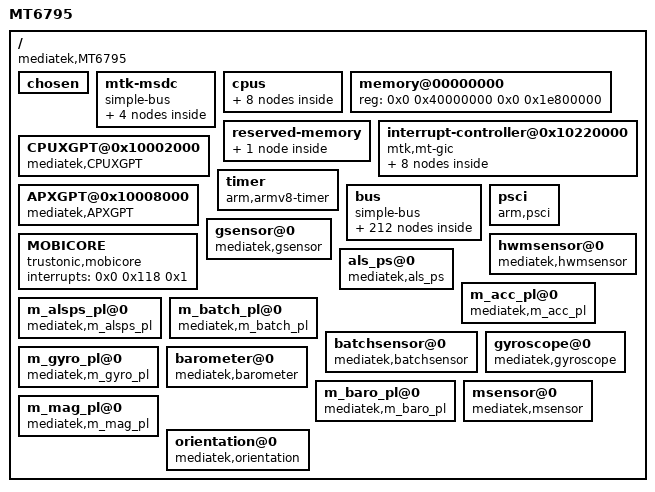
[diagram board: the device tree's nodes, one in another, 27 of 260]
/*
 * Mediatek's MT6795 SoC device tree source
 *
 * Copyright (c) 2013 MediaTek Co., Ltd.
 *              http://www.mediatek.com
 *
 */

/* Decompile from stock Xiaomi Redmi Note 2 kernel
 * By Anomalchik
 */

 
/dts-v1/;

/ {
	model = "MT6795";
	compatible = "mediatek,MT6795";
	interrupt-parent = <0x1>;
	#address-cells = <0x2>;
	#size-cells = <0x2>;

	chosen {
		bootargs = "console=tty0 console=ttyMT0,921600n1 root=/dev/ram initrd=0x44000000,0x300000 loglevel=8";
	};

	mtk-msdc {
		compatible = "simple-bus";
		#address-cells = <0x1>;
		#size-cells = <0x1>;
		ranges = <0x0 0x0 0x0 0xffffffff>;

		MSDC0@0x11230000 {
			compatible = "mediatek,MSDC0";
			reg = <0x11230000 0x10000 0x10001e84 0x2>;
			interrupts = <0x0 0x4f 0x8>;
		};

		MSDC1@0x11240000 {
			compatible = "mediatek,MSDC1";
			reg = <0x11240000 0x10000 0x10001e84 0x2>;
			interrupts = <0x0 0x50 0x8>;
		};

		MSDC2@0x11250000 {
			compatible = "mediatek,MSDC2";
			reg = <0x11250000 0x10000 0x10001e84 0x2>;
			interrupts = <0x0 0x51 0x8>;
		};

		MSDC3@0x11260000 {
			compatible = "mediatek,MSDC3";
			reg = <0x11260000 0x10000 0x10001e84 0x2>;
			interrupts = <0x0 0x52 0x8>;
		};
	};

	cpus {
		#address-cells = <0x1>;
		#size-cells = <0x0>;

		cpu@0 {
			device_type = "cpu";
			compatible = "arm,cortex-a53";
			reg = <0x0>;
			enable-method = "mt-boot";
			cpu-release-addr = <0x0 0x40000200>;
			clock-frequency = <0x77359400>;
			linux,phandle = <0x2>;
			phandle = <0x2>;
		};

		cpu@1 {
			device_type = "cpu";
			compatible = "arm,cortex-a53";
			reg = <0x1>;
			enable-method = "mt-boot";
			cpu-release-addr = <0x0 0x40000200>;
			clock-frequency = <0x77359400>;
			linux,phandle = <0x3>;
			phandle = <0x3>;
		};

		cpu@2 {
			device_type = "cpu";
			compatible = "arm,cortex-a53";
			reg = <0x2>;
			enable-method = "mt-boot";
			cpu-release-addr = <0x0 0x40000200>;
			clock-frequency = <0x77359400>;
			linux,phandle = <0x4>;
			phandle = <0x4>;
		};

		cpu@3 {
			device_type = "cpu";
			compatible = "arm,cortex-a53";
			reg = <0x3>;
			enable-method = "mt-boot";
			cpu-release-addr = <0x0 0x40000200>;
			clock-frequency = <0x77359400>;
			linux,phandle = <0x5>;
			phandle = <0x5>;
		};

		cpu@4 {
			device_type = "cpu";
			compatible = "arm,cortex-a53";
			reg = <0x100>;
			enable-method = "mt-boot";
			cpu-release-addr = <0x0 0x40000200>;
			clock-frequency = <0x77359400>;
			linux,phandle = <0x6>;
			phandle = <0x6>;
		};

		cpu@5 {
			device_type = "cpu";
			compatible = "arm,cortex-a53";
			reg = <0x101>;
			enable-method = "mt-boot";
			cpu-release-addr = <0x0 0x40000200>;
			clock-frequency = <0x77359400>;
			linux,phandle = <0x7>;
			phandle = <0x7>;
		};

		cpu@6 {
			device_type = "cpu";
			compatible = "arm,cortex-a53";
			reg = <0x102>;
			enable-method = "mt-boot";
			cpu-release-addr = <0x0 0x40000200>;
			clock-frequency = <0x77359400>;
			linux,phandle = <0x8>;
			phandle = <0x8>;
		};

		cpu@7 {
			device_type = "cpu";
			compatible = "arm,cortex-a53";
			reg = <0x103>;
			enable-method = "mt-boot";
			cpu-release-addr = <0x0 0x40000200>;
			clock-frequency = <0x77359400>;
			linux,phandle = <0x9>;
			phandle = <0x9>;
		};
	};

	memory@00000000 {
		device_type = "memory";
		reg = <0x0 0x40000000 0x0 0x1e800000>;
	};

	reserved-memory {
		#address-cells = <0x2>;
		#size-cells = <0x2>;
		ranges;

		reserve-memory-ccci_md1 {
			compatible = "reserve-memory-ccci_md1";
			no-map;
			size = <0x0 0x5200000>;
			alignment = <0x0 0x2000000>;
			alloc-ranges = <0x0 0x40000000 0x0 0xc0000000>;
		};
	};

	interrupt-controller@0x10220000 {
		compatible = "mtk,mt-gic";
		#interrupt-cells = <0x3>;
		#address-cells = <0x0>;
		interrupt-controller;
		reg = <0x0 0x10221000 0x0 0x1000 0x0 0x10222000 0x0 0x1000 0x0 0x10200620 0x0 0x1000>;
		interrupts = <0x1 0x9 0xf04>;
		linux,phandle = <0x1>;
		phandle = <0x1>;

		gic-cpuif@0 {
			compatible = "arm,gic-cpuif";
			cpuif-id = <0x0>;
			cpu = <0x2>;
		};

		gic-cpuif@1 {
			compatible = "arm,gic-cpuif";
			cpuif-id = <0x1>;
			cpu = <0x3>;
		};

		gic-cpuif@2 {
			compatible = "arm,gic-cpuif";
			cpuif-id = <0x2>;
			cpu = <0x4>;
		};

		gic-cpuif@3 {
			compatible = "arm,gic-cpuif";
			cpuif-id = <0x3>;
			cpu = <0x5>;
		};

		gic-cpuif@4 {
			compatible = "arm,gic-cpuif";
			cpuif-id = <0x4>;
			cpu = <0x6>;
		};

		gic-cpuif@5 {
			compatible = "arm,gic-cpuif";
			cpuif-id = <0x5>;
			cpu = <0x7>;
		};

		gic-cpuif@6 {
			compatible = "arm,gic-cpuif";
			cpuif-id = <0x6>;
			cpu = <0x8>;
		};

		gic-cpuif@7 {
			compatible = "arm,gic-cpuif";
			cpuif-id = <0x7>;
			cpu = <0x9>;
		};
	};

	CPUXGPT@0x10002000 {
		compatible = "mediatek,CPUXGPT";
		reg = <0x0 0x10200000 0x0 0x1000>;
		interrupts = <0x0 0x40 0x4 0x0 0x41 0x4 0x0 0x42 0x4 0x0 0x43 0x4 0x0 0x44 0x4 0x0 0x45 0x4 0x0 0x46 0x4 0x0 0x47 0x4>;
	};

	APXGPT@0x10008000 {
		compatible = "mediatek,APXGPT";
		reg = <0x0 0x10008000 0x0 0x1000>;
		interrupts = <0x0 0x98 0x8>;
		clock-frequency = <0xc65d40>;
	};

	timer {
		compatible = "arm,armv8-timer";
		interrupts = <0x1 0xd 0x8 0x1 0xe 0x8 0x1 0xb 0x8 0x1 0xa 0x8>;
		clock-frequency = <0xc65d40>;
	};

	bus {
		compatible = "simple-bus";
		#address-cells = <0x1>;
		#size-cells = <0x1>;
		ranges = <0x0 0x0 0x0 0xffffffff>;

		CKSYS@0x10000000 {
			compatible = "mediatek,CKSYS";
			reg = <0x10000000 0x1000>;
		};

		INFRACFG_AO@0x10001000 {
			compatible = "mediatek,INFRACFG_AO";
			reg = <0x10001000 0x1000>;
		};

		FHCTL@0x10209F00 {
			compatible = "mediatek,FHCTL";
			reg = <0x10209f00 0x100>;
		};

		PERICFG@0x10003000 {
			compatible = "mediatek,PERICFG";
			reg = <0x10003000 0x1000>;
		};

		DRAMC0@0x10004000 {
			compatible = "mediatek,DRAMC0";
			reg = <0x10004000 0x1000>;
			interrupts = <0x0 0x95 0x2>;
		};

		GPIO@0x10005000 {
			compatible = "mediatek,GPIO";
			reg = <0x10005000 0x1000>;
		};

		SLEEP@0x10006000 {
			compatible = "mediatek,SLEEP";
			reg = <0x10006000 0x1000>;
			interrupts = <0x0 0xa3 0x8 0x0 0xa4 0x8 0x0 0xa5 0x8 0x0 0xa6 0x8 0x0 0xa7 0x8 0x0 0xa8 0x8 0x0 0xa9 0x8 0x0 0xaa 0x8>;
		};

		TOPRGU@0x10007000 {
			compatible = "mediatek,TOPRGU";
			reg = <0x10007000 0x1000>;
			interrupts = <0x0 0x80 0x2>;
		};

		SEJ@0x1000A000 {
			compatible = "mediatek,SEJ";
			reg = <0x1000a000 0x1000>;
			interrupts = <0x0 0xac 0x8>;
		};

		EINTC@0x1000B000 {
			compatible = "mediatek,EINTC";
			reg = <0x1000b000 0x1000>;
			interrupts = <0x0 0x99 0x4>;
			deint_possible_irq = <0xbd 0xbe 0xbf 0xc0 0x0 0x0 0x0 0x0>;
			#interrupt-cells = <0x2>;
			interrupt-controller;
			linux,phandle = <0xa>;
			phandle = <0xa>;

			MSDC1_INS@1 {
				compatible = "mediatek, MSDC1_INS-eint";
				interrupt-parent = <0xa>;
				interrupts = <0x1 0x8>;
				debounce = <0x1 0x3e8>;
			};

			IRQ_NFC@3 {
				compatible = "mediatek, IRQ_NFC-eint";
				interrupt-parent = <0xa>;
				interrupts = <0x3 0x4>;
				debounce = <0x3 0x0>;
			};

			WIFI@4 {
				compatible = "mediatek, WIFI-eint";
				interrupt-parent = <0xa>;
				interrupts = <0x4 0x8>;
				debounce = <0x4 0x0>;
			};

			TOUCH_PANEL@6 {
				compatible = "mediatek, TOUCH_PANEL-eint";
				interrupt-parent = <0xa>;
				interrupts = <0x6 0x2>;
				debounce = <0x6 0x0>;
			};

			EXT_BUCK_OC@7 {
				compatible = "mediatek, EXT_BUCK_OC-eint";
				interrupt-parent = <0xa>;
				interrupts = <0x7 0x8>;
				debounce = <0x7 0x0>;
			};

			ALS@8 {
				compatible = "mediatek, ALS-eint";
				interrupt-parent = <0xa>;
				interrupts = <0x8 0x8>;
				debounce = <0x8 0x0>;
			};

			MSE@12 {
				compatible = "mediatek, MSE-eint";
				interrupt-parent = <0xa>;
				interrupts = <0xc 0x4>;
				debounce = <0xc 0x0>;
			};

			ACCDET@13 {
				compatible = "mediatek, ACCDET-eint";
				interrupt-parent = <0xa>;
				interrupts = <0xd 0x4>;
				debounce = <0xd 0x3e800>;
			};

			GYRO@105 {
				compatible = "mediatek, GYRO-eint";
				interrupt-parent = <0xa>;
				interrupts = <0x69 0x4>;
				debounce = <0x69 0x0>;
			};

			MHL@134 {
				compatible = "mediatek, MHL-eint";
				interrupt-parent = <0xa>;
				interrupts = <0x86 0x8>;
				debounce = <0x86 0x0>;
			};
		};

		SMI_COMMON@0x14022000 {
			compatible = "mediatek,SMI_COMMON";
			reg = <0x14022000 0x1000 0x14021000 0x1000 0x16010000 0x1000 0x15001000 0x1000 0x18001000 0x1000 0x17002000 0x1000>;
		};

		E3TCM@0x1000C000 {
			compatible = "mediatek,E3TCM";
			reg = <0x1000c000 0x1000>;
		};

		PMIC_WRAP@0x1000D000 {
			compatible = "mediatek,PMIC_WRAP";
			reg = <0x1000d000 0x1000>;
			interrupts = <0x0 0xa1 0x4>;
		};

		DEVAPC_AO@0x1000E000 {
			compatible = "mediatek,DEVAPC_AO";
			reg = <0x1000e000 0x1000>;
		};

		DDRPHY@0x1000F000 {
			compatible = "mediatek,DDRPHY";
			reg = <0x1000f000 0x1000>;
		};

		KP@0x10010000 {
			compatible = "mediatek,KP";
			reg = <0x10010000 0x1000>;
			interrupts = <0x0 0xa2 0x2>;
		};

		DRAMC1@0x10011000 {
			compatible = "mediatek,DRAMC1";
			reg = <0x10011000 0x1000>;
		};

		DDRPHY1@0x10012000 {
			compatible = "mediatek,DDRPHY1";
			reg = <0x10012000 0x1000>;
		};

		BAT_METTER {
			compatible = "mediatek,bat_meter";
		};

		BAT_NOTIFY {
			compatible = "mediatek,bat_notify";
		};

		SCP_SRAM@0x10020000 {
			compatible = "mediatek,SCP_SRAM";
			reg = <0x10020000 0x40000 0x10060000 0x80000>;
		};

		SCP_CFGREG@0x10050000 {
			compatible = "mediatek,SCP_CFGREG";
			reg = <0x10050000 0x400>;
			interrupts = <0x0 0xae 0x4>;
		};

		DBGAPB_BASE@0x1011A000 {
			compatible = "mediatek,DBGAPB_BASE";
			reg = <0x1011a000 0x100>;
		};

		MCUCFG@0x10200000 {
			compatible = "mediatek,MCUCFG";
			reg = <0x10200000 0x1000>;
			interrupts = <0x0 0x47 0x4>;
		};

		INFRACFG@0x10201000 {
			compatible = "mediatek,INFRACFG";
			reg = <0x10201000 0x1000>;
			interrupts = <0x0 0x8b 0x1>;
		};

		SRAMROM@0x10202000 {
			compatible = "mediatek,SRAMROM";
			reg = <0x10202000 0x1000>;
		};

		EMI@0x10203000 {
			compatible = "mediatek,EMI";
			reg = <0x10203000 0x1000>;
			interrupts = <0x0 0x88 0x8>;
		};

		SYS_CIRQ@0x10204000 {
			compatible = "mediatek,SYS_CIRQ";
			reg = <0x10204000 0x1000>;
			interrupts = <0x0 0xf0 0x8>;
			cirq_num = <0xa8>;
			spi_start_offset = <0x48>;
		};

		M4U@0x10205000 {
			cell-index = <0x0>;
			compatible = "mediatek,M4U";
			reg = <0x10205000 0x1000>;
			interrupts = <0x0 0x93 0x8>;
		};

		EFUSEC@0x10206000 {
			compatible = "mediatek,EFUSEC";
			reg = <0x10206000 0x1000>;
		};

		DEVAPC@0x10207000 {
			compatible = "mediatek,DEVAPC";
			reg = <0x10207000 0x1000>;
			interrupts = <0x0 0x86 0x8>;
		};

		BUS_DBG@0x10208000 {
			compatible = "mediatek,BUS_DBG";
			reg = <0x10208000 0x1000>;
			interrupts = <0x0 0x85 0x8>;
		};

		APMIXED@0x10209000 {
			compatible = "mediatek,APMIXED";
			reg = <0x10209000 0x1000>;
		};

		AP_CCIF0@0x1020A000 {
			compatible = "mediatek,AP_CCIF0";
			reg = <0x1020a000 0x1000>;
			interrupts = <0x0 0x8c 0x8>;
		};

		MD_CCIF0@0x1020B000 {
			compatible = "mediatek,MD_CCIF0";
			reg = <0x1020b000 0x1000>;
		};

		GPIO1@0x1020C000 {
			compatible = "mediatek,GPIO1";
			reg = <0x1020c000 0x1000>;
		};

		INFRA_MBIST@0x1020D000 {
			compatible = "mediatek,INFRA_MBIST";
			reg = <0x1020d000 0x1000>;
		};

		DRAMC_NAO@0x1020E000 {
			compatible = "mediatek,DRAMC_NAO";
			reg = <0x1020e000 0x1000>;
		};

		TRNG@0x1020F000 {
			compatible = "mediatek,TRNG";
			reg = <0x1020f000 0x1000>;
			interrupts = <0x0 0x8d 0x8>;
		};

		GCPU@0x10210000 {
			compatible = "mediatek,GCPU";
			reg = <0x10210000 0x1000>;
			interrupts = <0x0 0x96 0x8>;
		};

		GCP_NS@0x10211000 {
			compatible = "mediatek,GCP_NS";
			reg = <0x10211000 0x1000>;
		};

		GCE@0x10212000 {
			compatible = "mediatek,GCE";
			reg = <0x10212000 0x1000>;
			interrupts = <0x0 0x8f 0x8 0x0 0x90 0x8>;
		};

		CQDMA@0x10212c00 {
			compatible = "mediatek,CQDMA";
			reg = <0x10212c00 0x1000>;
			interrupts = <0x0 0x8f 0x8>;
			nr_channel = <0x1>;
		};

		DRAMC1_NAO@0x10213000 {
			compatible = "mediatek,DRAMC1_NAO";
			reg = <0x10213000 0x1000>;
		};

		PERISYS_IOMMU@0x10214000 {
			cell-index = <0x1>;
			compatible = "mediatek,PERISYS_IOMMU";
			reg = <0x10214000 0x1000>;
			interrupts = <0x0 0x91 0x8>;
		};

		MIPI_TX0@0x10215000 {
			compatible = "mediatek,MIPI_TX0";
			reg = <0x10215000 0x1000>;
		};

		MIPI_TX1@0x10216000 {
			compatible = "mediatek,MIPI_TX1";
			reg = <0x10216000 0x1000>;
		};

		MIPI_RX_ANA_CSI0@0x10217000 {
			compatible = "mediatek,MIPI_RX_ANA_CSI0";
			reg = <0x10217000 0x1000>;
		};

		MIPI_RX_ANA_CSI1@0x10218000 {
			compatible = "mediatek,MIPI_RX_ANA_CSI1";
			reg = <0x10218000 0x1000>;
		};

		MIPI_RX_ANA_CSI2@0x10219000 {
			compatible = "mediatek,MIPI_RX_ANA_CSI2";
			reg = <0x10219000 0x1000>;
		};

		CA9@0x10220000 {
			compatible = "mediatek,CA9";
			reg = <0x10220000 0x8000>;
		};

		DBGAPB@0x10100000 {
			compatible = "mediatek,DBGAPB";
			reg = <0x10100000 0x1>;
			interrupts = <0x0 0x84 0x8>;
		};

		CCI400@0x10390000 {
			compatible = "mediatek,CCI400";
			reg = <0x10390000 0x10000>;
		};

		CPU_DBGAPB {
			compatible = "mediatek,DBG_DEBUG";
			num = <0x8>;
			reg = <0x10810000 0x1000 0x10910000 0x1000 0x10a10000 0x1000 0x10b10000 0x1000 0x10c10000 0x1000 0x10d10000 0x1000 0x10e10000 0x1000 0x10f10000 0x1000>;
		};

		AP_DMA@0x11000000 {
			compatible = "mediatek,AP_DMA";
			reg = <0x11000000 0x1000>;
			interrupts = <0x0 0x6e 0x8>;
		};

		AUXADC@0x11001000 {
			compatible = "mediatek,AUXADC";
			reg = <0x11001000 0x1000>;
			interrupts = <0x0 0x4c 0x2>;
		};

		AP_DMA_UART0_TX@0x11000380 {
			compatible = "mediatek,AP_DMA_UART0_TX";
			reg = <0x11000380 0x80>;
			interrupts = <0x0 0x67 0x8>;
		};

		AP_DMA_UART0_RX@0x11000400 {
			compatible = "mediatek,AP_DMA_UART0_RX";
			reg = <0x11000400 0x80>;
			interrupts = <0x0 0x68 0x8>;
		};

		AP_DMA_UART1_TX@0x11000480 {
			compatible = "mediatek,AP_DMA_UART1_TX";
			reg = <0x11000480 0x80>;
			interrupts = <0x0 0x69 0x8>;
		};

		AP_DMA_UART1_RX@0x11000500 {
			compatible = "mediatek,AP_DMA_UART1_RX";
			reg = <0x11000500 0x80>;
			interrupts = <0x0 0x6a 0x8>;
		};

		AP_DMA_UART2_TX@0x11000580 {
			compatible = "mediatek,AP_DMA_UART2_TX";
			reg = <0x11000580 0x80>;
			interrupts = <0x0 0x6b 0x8>;
		};

		AP_DMA_UART2_RX@0x11000600 {
			compatible = "mediatek,AP_DMA_UART2_RX";
			reg = <0x11000600 0x80>;
			interrupts = <0x0 0x6c 0x8>;
		};

		AP_DMA_UART3_TX@0x11000680 {
			compatible = "mediatek,AP_DMA_UART3_TX";
			reg = <0x11000680 0x80>;
			interrupts = <0x0 0x6d 0x8>;
		};

		AP_DMA_UART3_RX@0x11000700 {
			compatible = "mediatek,AP_DMA_UART3_RX";
			reg = <0x11000700 0x80>;
			interrupts = <0x0 0x6e 0x8>;
		};

		AP_UART0@0x11002000 {
			cell-index = <0x0>;
			compatible = "mediatek,AP_UART0";
			reg = <0x11002000 0x1000>;
			interrupts = <0x0 0x5b 0x8>;
		};

		AP_UART1@0x11003000 {
			cell-index = <0x1>;
			compatible = "mediatek,AP_UART1";
			reg = <0x11003000 0x1000>;
			interrupts = <0x0 0x5c 0x8>;
		};

		AP_UART2@0x11004000 {
			cell-index = <0x2>;
			compatible = "mediatek,AP_UART2";
			reg = <0x11004000 0x1000>;
			interrupts = <0x0 0x5d 0x8>;
		};

		AP_UART3@0x11005000 {
			cell-index = <0x3>;
			compatible = "mediatek,AP_UART3";
			reg = <0x11005000 0x1000>;
			interrupts = <0x0 0x5e 0x8>;
		};

		PWM@0x11006000 {
			compatible = "mediatek,PWM";
			reg = <0x11006000 0x1000>;
			interrupts = <0x0 0x4d 0x8>;
		};

		I2C0@0x11007000 {
			compatible = "mediatek,I2C0";
			cell-index = <0x0>;
			reg = <0x11007000 0x1000>;
			interrupts = <0x0 0x54 0x8>;
			def_speed = <0x64>;
		};

		I2C1@0x11008000 {
			compatible = "mediatek,I2C1";
			cell-index = <0x1>;
			reg = <0x11008000 0x1000>;
			interrupts = <0x0 0x55 0x8>;
			def_speed = <0x6e>;
		};

		I2C2@0x11009000 {
			compatible = "mediatek,I2C2";
			cell-index = <0x2>;
			reg = <0x11009000 0x1000>;
			interrupts = <0x0 0x56 0x8>;
			def_speed = <0x78>;
		};

		I2C3@0x11010000 {
			compatible = "mediatek,I2C3";
			cell-index = <0x3>;
			reg = <0x11010000 0x1000>;
			interrupts = <0x0 0x57 0x8>;
			def_speed = <0x82>;
		};

		I2C4@0x11011000 {
			compatible = "mediatek,I2C4";
			cell-index = <0x4>;
			reg = <0x11011000 0x1000>;
			interrupts = <0x0 0x58 0x8>;
			def_speed = <0x8c>;
		};

		SPI1@0x1100A000 {
			compatible = "mediatek,SPI1";
			reg = <0x1100a000 0x1000>;
			interrupts = <0x0 0x76 0x8>;
			cell-index = <0x0>;
		};

		THERM_CTRL@0x1100B000 {
			compatible = "mediatek,THERM_CTRL";
			reg = <0x1100b000 0x1000>;
			interrupts = <0x0 0x4e 0x8>;
		};

		PTP_FSM@0x1100B000 {
			compatible = "mediatek,PTP_FSM";
			reg = <0x1100b000 0x1000>;
			interrupts = <0x0 0x7d 0x8>;
		};

		IRDA_FRAMER@0x1100C000 {
			compatible = "mediatek,IRDA_FRAMER";
			reg = <0x1100c000 0x1000>;
			interrupts = <0x0 0x61 0x8>;
		};

		mt3326-gps@0xffffffff {
			compatible = "mediatek,mt3326-gps";
		};

		NFI@0x1100D000 {
			compatible = "mediatek,NFI";
			reg = <0x1100d000 0x1000>;
			interrupts = <0x0 0x60 0x8>;
		};

		NFIECC@0x1100E000 {
			compatible = "mediatek,NFIECC";
			reg = <0x1100e000 0x1000>;
			interrupts = <0x0 0x5f 0x8>;
		};

		NLI_ARB@0x1100F000 {
			compatible = "mediatek,NLI_ARB";
			reg = <0x1100f000 0x1000>;
		};

		USB0@0x11200000 {
			compatible = "mediatek,USB0";
			cell-index = <0x0>;
			reg = <0x11200000 0x10000 0x11210000 0x10000>;
			interrupts = <0x0 0x49 0x8>;
			mode = <0x2>;
			multipoint = <0x1>;
			dyn_fifo = <0x1>;
			soft_con = <0x1>;
			dma = <0x1>;
			num_eps = <0x10>;
			dma_channels = <0x8>;
		};

		AUDIO@0x11220000 {
			compatible = "mediatek,AUDIO";
			reg = <0x11220000 0x10000>;
			interrupts = <0x0 0x8e 0x8>;
		};

		MT_SOC_DL1_PCM@0x11220000 {
			compatible = "mediatek,mt_soc_pcm_dl1";
			reg = <0x11220000 0x1000>;
			interrupts = <0x0 0x8e 0x8>;
		};

		MT_SOC_UL1_PCM@0x11220000 {
			compatible = "mediatek,mt_soc_pcm_capture";
		};

		MT_SOC_HDMI_PCM@0x11220000 {
			compatible = "mediatek,mt_soc_pcm_hdmi";
		};

		MT_SOC_ULDLLOOPBACK_PCM@0x11220000 {
			compatible = "mediatek,mt_soc_pcm_uldlloopback";
		};

		MT_SOC_VOICE@0x11220000 {
			compatible = "mediatek,mt_soc_pcm_voice";
		};

		MT_SOC_VOICE_BT@0x11220000 {
			compatible = "mediatek,mt_soc_pcm_voice_bt";
		};

		MT_SOC_VOICE_EXT@0x11220000 {
			compatible = "mediatek,mt_soc_pcm_voice_ext";
		};

		MT_SOC_VOICE_EXT_BT@0x11220000 {
			compatible = "mediatek,mt_soc_pcm_voice_ext_bt";
		};

		MT_SOC_VOICE_EXTINT@0x11220000 {
			compatible = "mediatek,mt_soc_pcm_voice_extint";
		};

		MT_SOC_VOICE_EXTINT_BT@0x11220000 {
			compatible = "mediatek,mt_soc_pcm_voice_extint_bt";
		};

		MT_SOC_I2S0_PCM@0x11220000 {
			compatible = "mediatek,mt_soc_pcm_dl1_i2s0";
		};

		MT_SOC_MRGRX_PCM@0x11220000 {
			compatible = "mediatek,mt_soc_pcm_mrgrx";
		};

		MT_SOC_MRGRX_AWB_PCM@0x11220000 {
			compatible = "mediatek,mt_soc_pcm_mrgrx_awb";
		};

		MT_SOC_I2S0DL1_PCM@0x11220000 {
			compatible = "mediatek,mt_soc_pcm_dl1_i2s0Dl1";
		};

		MT_SOC_DL1_AWB_PCM@0x11220000 {
			compatible = "mediatek,mt_soc_pcm_dl1_awb";
		};

		MT_SOC_VOIP_BT_OUT@0x11220000 {
			compatible = "mediatek,mt_soc_pcm_dl1_bt";
		};

		MT_SOC_ADC2_ADCI2S2_PCM@0x11220000 {
			compatible = "mediatek,mt_soc_pcm_adc2_adci2s2";
		};

		MT_SOC_VOIP_BT_IN@0x11220000 {
			compatible = "mediatek,mt_soc_pcm_bt_dai";
		};

		MT_SOC_TDMRX_PCM@0x11220000 {
			compatible = "mediatek,mt_soc_tdm_capture";
		};

		MT_SOC_FM_MRGTX_PCM@0x11220000 {
			compatible = "mediatek,mt_soc_pcm_fmtx";
		};

		MT_SOC_UL2_PCM@0x11220000 {
			compatible = "mediatek,mt_soc_pcm_capture2";
		};

		MT_SOC_I2S0_AWB_PCM@0x11220000 {
			compatible = "mediatek,mt_soc_pcm_i2s0_awb";
		};

		MT_SOC_IO2_AWB_PCM@0x11220000 {
			compatible = "mediatek,mt_soc_pcm_io2_awb";
		};

		MT_SOC_MOD_ADCI2S_PCM@0x11220000 {
			compatible = "mediatek,mt_soc_pcm_mod_adci2s";
		};

		MT_SOC_MOD_DAI_PCM@0x11220000 {
			compatible = "mediatek,mt_soc_pcm_mod_dai";
		};

		MT_SOC_ROUTING_PCM@0x11220000 {
			compatible = "mediatek,mt_soc_pcm_routing";
			i2s1clk-gpio = <0xc1 0x2>;
			i2s1dat-gpio = <0xc3 0x2>;
			i2s1dat1-gpio = <0xc4 0x2>;
			i2s1mclk-gpio = <0xc2 0x2>;
			i2s1ws-gpio = <0xc0 0x2>;
		};

		MT_SOC_HP_IMPEDANCE_PCM@0x11220000 {
			compatible = "mediatek,Mt_soc_pcm_hp_impedance";
		};

		MT_SOC_CODEC_NAME@0x11220000 {
			compatible = "mediatek,mt_soc_codec_63xx";
		};

		MT_SOC_DUMMY_PCM@0x11220000 {
			compatible = "mediatek,mt_soc_pcm_dummy";
		};

		MT_SOC_CODEC_DUMMY_NAME@0x11220000 {
			compatible = "mediatek,mt_soc_codec_dummy";
		};

		MT_SOC_ROUTING_DAI_NAME@0x11220000 {
			compatible = "mediatek,mt_soc_dai_routing";
		};

		MT_SOC_DAI_NAME@0x11220000 {
			compatible = "mediatek,mt_soc_dai_stub";
		};

		USB3@0x11270000 {
			compatible = "mediatek,USB3";
			reg = <0x11270000 0x10000 0x11280000 0x10000 0x11290000 0x10000>;
			reg-names = "ssusb_base", "ssusb_sif", "ssusb_sif2";
			interrupts = <0x0 0x7a 0x8 0x0 0x7b 0x8>;
			interrupt-names = "musb-hdrc", "xhci";
		};

		USB3_XHCI@0x11270000 {
			compatible = "mediatek,USB3_XHCI";
			reg = <0x11270000 0x10000 0x11280000 0x10000 0x11290000 0x10000>;
			reg-names = "ssusb_base", "ssusb_sif", "ssusb_sif2";
			interrupts = <0x0 0x7b 0x8>;
			iddig-gpio-num = <0x10>;
			interrupt-names = "xhci";
		};

		USB3_SIF@0x11280000 {
			compatible = "mediatek,USB3_SIF";
			reg = <0x11280000 0x10000>;
		};

		USB3_SIF2@0x11290000 {
			compatible = "mediatek,USB3_SIF2";
			reg = <0x11290000 0x10000>;
		};

		BATTERY {
			compatible = "mediatek,battery";
		};

		MFGCFG@0x13FFF000 {
			compatible = "mediatek,MFGCFG";
			reg = <0x13fff000 0x1000>;
		};

		HAN@0x13000000 {
			compatible = "mediatek,HAN";
			reg = <0x13000000 0xffff>;
			interrupts = <0x0 0xe1 0x8>;
			interrupt-names = "RGX";
			clock-frequency = <0x284af100>;
		};

		MMSYS_CONFIG@0x14000000 {
			compatible = "mediatek,MMSYS_CONFIG";
			reg = <0x14000000 0x1000>;
			interrupts = <0x0 0xcb 0x8>;
		};

		MDP_RDMA0@0x14001000 {
			compatible = "mediatek,MDP_RDMA0";
			reg = <0x14001000 0x1000>;
			interrupts = <0x0 0xb2 0x8>;
		};

		MDP_RDMA1@0x14002000 {
			compatible = "mediatek,MDP_RDMA1";
			reg = <0x14002000 0x1000>;
			interrupts = <0x0 0xb3 0x8>;
		};

		MDP_RSZ0@0x14003000 {
			compatible = "mediatek,MDP_RSZ0";
			reg = <0x14003000 0x1000>;
			interrupts = <0x0 0xb4 0x8>;
		};

		MDP_RSZ1@0x14004000 {
			compatible = "mediatek,MDP_RSZ1";
			reg = <0x14004000 0x1000>;
			interrupts = <0x0 0xb5 0x8>;
		};

		MDP_RSZ2@0x14005000 {
			compatible = "mediatek,MDP_RSZ2";
			reg = <0x14005000 0x1000>;
			interrupts = <0x0 0xb6 0x8>;
		};

		MDP_WDMA@0x14006000 {
			compatible = "mediatek,MDP_WDMA";
			reg = <0x14006000 0x1000>;
			interrupts = <0x0 0xb9 0x8>;
		};

		MDP_WROT0@0x14007000 {
			compatible = "mediatek,MDP_WROT0";
			reg = <0x14007000 0x1000>;
			interrupts = <0x0 0xba 0x8>;
		};

		MDP_WROT1@0x14008000 {
			compatible = "mediatek,MDP_WROT1";
			reg = <0x14008000 0x1000>;
			interrupts = <0x0 0xbb 0x8>;
		};

		MDP_TDSHP0@0x14009000 {
			compatible = "mediatek,MDP_TDSHP0";
			reg = <0x14009000 0x1000>;
			interrupts = <0x0 0xb7 0x8>;
		};

		MDP_TDSHP1@0x1400A000 {
			compatible = "mediatek,MDP_TDSHP1";
			reg = <0x1400a000 0x1000>;
			interrupts = <0x0 0xb8 0x8>;
		};

		MDP_CROP@0x1400B000 {
			compatible = "mediatek,MDP_CROP";
			reg = <0x1400b000 0x1000>;
		};

		DISPSYS@0x10002000 {
			compatible = "mediatek,DISPSYS";
			reg = <0x14000000 0x1000 0x1400c000 0x1000 0x1400d000 0x1000 0x1400e000 0x1000 0x1400f000 0x1000 0x14010000 0x1000 0x14011000 0x1000 0x14012000 0x1000 0x14013000 0x1000 0x14014000 0x1000 0x14015000 0x1000 0x14016000 0x1000 0x14017000 0x1000 0x14018000 0x1000 0x14019000 0x1000 0x1401a000 0x1000 0x1401b000 0x1000 0x1401c000 0x1000 0x1401d000 0x1000 0x1401e000 0x1000 0x1401f000 0x1000 0x14020000 0x1000 0x14021000 0x1000 0x14022000 0x1000 0x14023000 0x1000 0x10215000 0x1000 0x10216000 0x1000>;
			interrupts = <0x0 0x0 0x8 0x0 0xbc 0x8 0x0 0xbd 0x8 0x0 0xbe 0x8 0x0 0xbf 0x8 0x0 0xc0 0x8 0x0 0xc1 0x8 0x0 0xc2 0x8 0x0 0xc3 0x8 0x0 0xc4 0x8 0x0 0xc5 0x8 0x0 0xc6 0x8 0x0 0x0 0x8 0x0 0x0 0x8 0x0 0x0 0x8 0x0 0xc7 0x8 0x0 0xc8 0x8 0x0 0xc9 0x8 0x0 0xca 0x8 0x0 0x0 0x8 0x0 0x0 0x8 0x0 0xb1 0x8 0x0 0x0 0x8 0x0 0x0 0x8 0x0 0xcc 0x8 0x0 0x8a 0x8 0x0 0x8b 0x8>;
		};

		DISP_OVL0@0x1400C000 {
			compatible = "mediatek,DISP_OVL0";
			reg = <0x1400c000 0x1000>;
		};

		DISP_OVL1@0x1400D000 {
			compatible = "mediatek,DISP_OVL1";
			reg = <0x1400d000 0x1000>;
		};

		DISP_RDMA0@0x1400E000 {
			compatible = "mediatek,DISP_RDMA0";
			reg = <0x1400e000 0x1000>;
			interrupts = <0x0 0xbe 0x8>;
		};

		DISP_RDMA1@0x1400F000 {
			compatible = "mediatek,DISP_RDMA1";
			reg = <0x1400f000 0x1000>;
			interrupts = <0x0 0xbf 0x8>;
		};

		DISP_RDMA2@0x14010000 {
			compatible = "mediatek,DISP_RDMA2";
			reg = <0x14010000 0x1000>;
			interrupts = <0x0 0xc0 0x8>;
		};

		DISP_WDMA0@0x14011000 {
			compatible = "mediatek,DISP_WDMA0";
			reg = <0x14011000 0x1000>;
			interrupts = <0x0 0xc1 0x8>;
		};

		DISP_WDMA1@0x14012000 {
			compatible = "mediatek,DISP_WDMA1";
			reg = <0x14012000 0x1000>;
			interrupts = <0x0 0xc2 0x8>;
		};

		DISP_COLOR0@0x14013000 {
			compatible = "mediatek,DISP_COLOR0";
			reg = <0x14013000 0x1000>;
		};

		DISP_COLOR1@0x14014000 {
			compatible = "mediatek,DISP_COLOR1";
			reg = <0x14014000 0x1000>;
		};

		DISP_AAL@0x14015000 {
			compatible = "mediatek,DISP_AAL";
			reg = <0x14015000 0x1000>;
			interrupts = <0x0 0xc5 0x8>;
		};

		DISP_GAMMA@0x14016000 {
			compatible = "mediatek,DISP_GAMMA";
			reg = <0x14016000 0x1000>;
			interrupts = <0x0 0xc6 0x8>;
		};

		DISP_MERGE@0x14017000 {
			compatible = "mediatek,DISP_MERGE";
			reg = <0x14017000 0x1000>;
		};

		DISP_SPLIT0@0x14018000 {
			compatible = "mediatek,DISP_SPLIT0";
			reg = <0x14018000 0x1000>;
		};

		DISP_SPLIT1@0x14019000 {
			compatible = "mediatek,DISP_SPLIT1";
			reg = <0x14019000 0x1000>;
		};

		DISP_UFOE@0x1401A000 {
			compatible = "mediatek,DISP_UFOE";
			reg = <0x1401a000 0x1000>;
			interrupts = <0x0 0xc7 0x8>;
		};

		DSI0@0x1401B000 {
			compatible = "mediatek,DSI0";
			reg = <0x1401b000 0x1000>;
			interrupts = <0x0 0xc8 0x8>;
		};

		DSI1@0x1401C000 {
			compatible = "mediatek,DSI1";
			reg = <0x1401c000 0x1000>;
			interrupts = <0x0 0xc9 0x8>;
		};

		DPI@0x1401D000 {
			compatible = "mediatek,DPI";
			reg = <0x1401d000 0x1000>;
			interrupts = <0x0 0xca 0x8>;
		};

		HDMI@0 {
			compatible = "mediatek,HDMI";
		};

		DISP_PWM0@0x1401E000 {
			compatible = "mediatek,DISP_PWM0";
			reg = <0x1401e000 0x1000>;
		};

		DISP_PWM1@0x1401F000 {
			compatible = "mediatek,DISP_PWM1";
			reg = <0x1401f000 0x1000>;
		};

		MM_MUTEX@0x14020000 {
			compatible = "mediatek,MM_MUTEX";
			reg = <0x14020000 0x1000>;
			interrupts = <0x0 0xb1 0x8>;
		};

		SMI_LARB0@0x14021000 {
			compatible = "mediatek,SMI_LARB0";
			reg = <0x14021000 0x1000>;
			interrupts = <0x0 0xcd 0x8>;
		};

		DISP_OD@0x14023000 {
			compatible = "mediatek,DISP_OD";
			reg = <0x14023000 0x1000>;
			interrupts = <0x0 0xcc 0x8>;
		};

		ISPSYS@0x15000000 {
			compatible = "mediatek,ISPSYS";
			reg = <0x15004000 0x9000 0x1500d000 0x1000 0x15000000 0x10000 0x10217000 0x3000 0x10005000 0x1000>;
			interrupts = <0x0 0xdb 0x8 0x0 0xdc 0x8 0x0 0xdd 0x8 0x0 0xde 0x8 0x0 0xdf 0x8>;
		};

		IMGSYS@0x15000000 {
			compatible = "mediatek,IMGSYS";
			reg = <0x15000000 0x1000>;
		};

		SMI_LARB2@0x15001000 {
			compatible = "mediatek,SMI_LARB2";
			reg = <0x15001000 0x1000>;
			interrupts = <0x0 0xd9 0x8>;
		};

		CAM1@0x15004000 {
			compatible = "mediatek,CAM1";
			reg = <0x15004000 0x1000>;
			interrupts = <0x0 0xdd 0x8>;
		};

		CAM2@0x15005000 {
			compatible = "mediatek,CAM2";
			reg = <0x15005000 0x1000>;
		};

		CAM3@0x15006000 {
			compatible = "mediatek,CAM3";
			reg = <0x15006000 0x1000>;
		};

		CAM4@0x15007000 {
			compatible = "mediatek,CAM4";
			reg = <0x15007000 0x1000>;
		};

		KD_CAMERA_HW1@0x15008000 {
			compatible = "mediatek,CAMERA_HW";
			reg = <0x15008000 0x1000>;
		};

		KD_CAMERA_HW2@0x15008000 {
			compatible = "mediatek,CAMERA_HW2";
			reg = <0x15008000 0x1000>;
		};

		SENINF@0x15008000 {
			compatible = "mediatek,SENINF";
			reg = <0x15008000 0x1000>;
			interrupts = <0x0 0xda 0x8>;
		};

		CAMSV@0x15009000 {
			compatible = "mediatek,CAMSV";
			reg = <0x15009000 0x1000>;
			interrupts = <0x0 0xdf 0x8>;
		};

		FDVT@0x1500B000 {
			compatible = "mediatek,FDVT";
			reg = <0x1500b000 0x1000>;
			interrupts = <0x0 0xe0 0x8>;
		};

		MIPI_RX@0x1500C000 {
			compatible = "mediatek,MIPI_RX";
			reg = <0x1500c000 0x1000>;
		};

		CAM1_INNER@0x1500D000 {
			compatible = "mediatek,CAM1_INNER";
			reg = <0x1500d000 0x1000>;
		};

		CAM3_INNER@0x1500E000 {
			compatible = "mediatek,CAM3_INNER";
			reg = <0x1500e000 0x1000>;
		};

		CAM4_INNER@0x1500F000 {
			compatible = "mediatek,CAM4_INNER";
			reg = <0x1500f000 0x1000>;
		};

		VDEC_GCON@0x16000000 {
			compatible = "mediatek,VDEC_GCON";
			reg = <0x16000000 0x10000>;
		};

		SMI_LARB1@16010000 {
			compatible = "mediatek,SMI_LARB1";
			reg = <0x16010000 0x10000>;
			interrupts = <0x0 0xd5 0x8>;
		};

		VDEC@16020000 {
			compatible = "mediatek,VDEC";
			reg = <0x16020000 0x10000>;
			interrupts = <0x0 0xd4 0x8>;
		};

		VLD@16021000 {
			compatible = "mediatek,VLD";
			reg = <0x16021000 0x800>;
		};

		VLD_TOP@16021800 {
			compatible = "mediatek,VLD_TOP";
			reg = <0x16021800 0x800>;
		};

		MC@16022000 {
			compatible = "mediatek,MC";
			reg = <0x16022000 0x1000>;
		};

		AVC_VLD@16023000 {
			compatible = "mediatek,AVC_VLD";
			reg = <0x16023000 0x1000>;
		};

		AVC_MV@16024000 {
			compatible = "mediatek,AVC_MV";
			reg = <0x16024000 0x1000>;
		};

		VDEC_PP@16025000 {
			compatible = "mediatek,VDEC_PP";
			reg = <0x16025000 0x1000>;
		};

		VP8_VLD@16026800 {
			compatible = "mediatek,VP8_VLD";
			reg = <0x16026800 0x800>;
		};

		VLD2@16027800 {
			compatible = "mediatek,VLD2";
			reg = <0x16027800 0x800>;
		};

		HEVC_VLD@16028000 {
			compatible = "mediatek,HEVC_VLD";
			reg = <0x16028000 0x1000>;
		};

		MJC_CONFIG@0x17000000 {
			compatible = "mediatek,MJC_CONFIG";
			reg = <0x17000000 0x1000>;
			interrupts = <0x0 0xd8 0x8>;
		};

		MJC_TOP@0x17001000 {
			compatible = "mediatek,MJC_TOP";
			reg = <0x17001000 0x1000>;
			interrupts = <0x0 0xd7 0x8>;
		};

		SMI_LARB5@0x17002000 {
			compatible = "mediatek,SMI_LARB5";
			reg = <0x17002000 0x1000>;
			interrupts = <0x0 0xd6 0x8>;
		};

		VENC_GCON@0x18000000 {
			compatible = "mediatek,VENC_GCON";
			reg = <0x18000000 0x1000>;
		};

		SMI_LARB3@0x18001000 {
			compatible = "mediatek,SMI_LARB3";
			reg = <0x18001000 0x1000>;
			interrupts = <0x0 0xcf 0x8>;
		};

		VENC@0x18002000 {
			compatible = "mediatek,VENC";
			reg = <0x18002000 0x1000>;
			interrupts = <0x0 0xce 0x8>;
		};

		JPGENC@0x18003000 {
			compatible = "mediatek,JPGENC";
			reg = <0x18003000 0x1000>;
			interrupts = <0x0 0xd0 0x8>;
		};

		JPGDEC@0x18004000 {
			compatible = "mediatek,JPGDEC";
			reg = <0x18004000 0x1000>;
			interrupts = <0x0 0xd3 0x8>;
		};

		MD_RGU@0x20050000 {
			compatible = "mediatek,MD_RGU";
			reg = <0x20050000 0x1000>;
			interrupts = <0x0 0xe9 0x2>;
		};

		MDCLDMA@0x200F0000 {
			compatible = "mediatek,MDCLDMA";
			reg = <0x200f0000 0x3000 0x200e0000 0x3000 0x1020a000 0x1000>;
			cell-index = <0x0>;
			interrupts = <0x0 0xea 0x4 0x0 0x8c 0x8 0x0 0xe9 0x2>;
			cldma,major = <0xb8>;
			cldma,minor_base = <0x0>;
			cldma,capability = <0x2>;
			md_smem_size = <0x200000>;
		};

		MTKFB@0 {
			compatible = "mediatek,MTKFB";
		};

		CHIPID@08000000 {
			compatible = "mediatek,CHIPID";
			reg = <0x8000000 0x4 0x8000004 0x4 0x8000008 0x4 0x800000c 0x4>;
		};

		uibc@0 {
			compatible = "mediatek,uibc";
		};

		gpio@0x10001e84 {
			compatible = "mediatek,fpga_gpio";
			reg = <0x10001e84 0x100>;
		};
	};

	psci {
		compatible = "arm,psci";
		method = "smc";
		cpu_suspend = <0x84000001>;
		cpu_off = <0x84000002>;
		cpu_on = <0x84000003>;
		affinity_info = <0x84000004>;
	};

	MOBICORE {
		compatible = "trustonic,mobicore";
		interrupts = <0x0 0x118 0x1>;
	};

	hwmsensor@0 {
		compatible = "mediatek,hwmsensor";
	};

	gsensor@0 {
		compatible = "mediatek,gsensor";
	};

	als_ps@0 {
		compatible = "mediatek,als_ps";
	};

	m_acc_pl@0 {
		compatible = "mediatek,m_acc_pl";
	};

	m_alsps_pl@0 {
		compatible = "mediatek,m_alsps_pl";
	};

	m_batch_pl@0 {
		compatible = "mediatek,m_batch_pl";
	};

	batchsensor@0 {
		compatible = "mediatek,batchsensor";
	};

	gyroscope@0 {
		compatible = "mediatek,gyroscope";
	};

	m_gyro_pl@0 {
		compatible = "mediatek,m_gyro_pl";
	};

	barometer@0 {
		compatible = "mediatek,barometer";
	};

	m_baro_pl@0 {
		compatible = "mediatek,m_baro_pl";
	};

	msensor@0 {
		compatible = "mediatek,msensor";
	};

	m_mag_pl@0 {
		compatible = "mediatek,m_mag_pl";
	};

	orientation@0 {
		compatible = "mediatek,orientation";
	};
};
